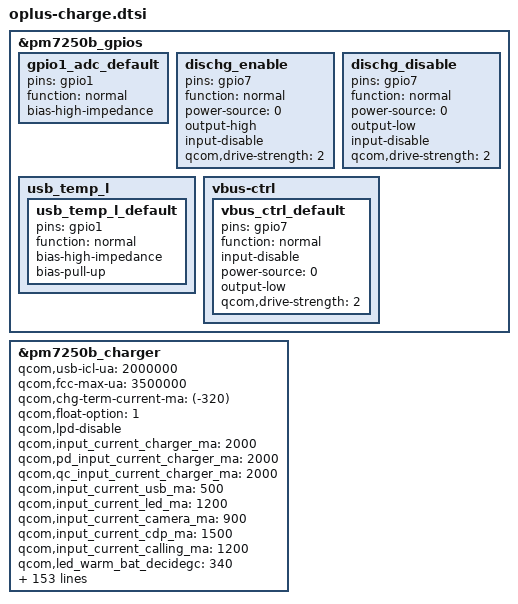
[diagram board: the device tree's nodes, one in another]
&pm7250b_gpios {
	gpio1_adc_default: gpio1_adc_default {
		pins = "gpio1"; /* GPIO 1 */
		function = "normal"; /* normal */
		bias-high-impedance; /* DISABLE GPIO1 for ADC*/
	};

	dischg_enable: dischg_enable {
		pins = "gpio7";
		function = "normal";
		power-source = <0>;
		output-high;
		input-disable;
		qcom,drive-strength = <2>;
	};

	dischg_disable: dischg_disable {
		pins = "gpio7";
		function = "normal";
		power-source = <0>;
		output-low;
		input-disable;
		qcom,drive-strength = <2>;
	};

	usb_temp_l {
		usb_temp_l_default: usb_temp_l_default {
			pins = "gpio1";
			function = "normal"; /* normal */
			bias-high-impedance;
			bias-pull-up;
		};
	};

	vbus-ctrl {
		vbus_ctrl_default: vbus_ctrl_default {
			pins = "gpio7";
			function = "normal";
			input-disable;
			power-source = <0>;
			output-low;
			qcom,drive-strength = <2>;
		};
	};
};


&pm7250b_charger {
	/* qcom options */
	qcom,usb-icl-ua = <2000000>;
	qcom,fcc-max-ua = <3500000>;
	qcom,chg-term-current-ma = <(-320)>;
	/*qcom,hvdcp-disable;*/
	qcom,float-option = <1>;
	qcom,lpd-disable;

	//for oplus chg framework:
	qcom,input_current_charger_ma = <2000>;
	qcom,pd_input_current_charger_ma = <2000>;
	qcom,qc_input_current_charger_ma = <2000>;
	qcom,input_current_usb_ma = <500>;
	qcom,input_current_led_ma = <1200>;
	qcom,input_current_camera_ma = <900>;
	qcom,input_current_cdp_ma = <1500>;
	qcom,input_current_calling_ma = <1200>;

	qcom,led_warm_bat_decidegc = <340>;	/* 34C ~ 37C */
	qcom,led_high_bat_decidegc = <370>;	/* > 37C */
	qcom,input_current_led_ma_normal = <2000>;	/* <= 34C */
	qcom,input_current_led_ma_warm = <1500>;	/* 34C ~ 37C */
	qcom,input_current_led_ma_high = <1000>;	/* > 37C */

	qcom,iterm_ma = <260>; 			/* 0.05C + 10mA */
	qcom,recharge-mv = <100>;
	qcom,batt_capacity_mah = <4890>;	/* rated capacity */

	qcom,removed_bat_decidegc = <400>;	/* < -40C */

	qcom,cold_bat_decidegc = <20>;		/* -2C ~ 0C */
	qcom,temp_cold_vfloat_mv = <3980>;
	qcom,temp_cold_fastchg_current_ma = <0>;

	qcom,little_cold_bat_decidegc = <0>;	/* 0C ~ 5C */
	qcom,temp_little_cold_vfloat_mv = <4425>;
	qcom,temp_little_cold_fastchg_current_ma = <2350>;
	qcom,temp_little_cold_fastchg_current_ma_high = <2350>;
	qcom,temp_little_cold_fastchg_current_ma_low = <1400>;
	qcom,qc_temp_little_cold_fastchg_current_ma_high = <2350>;
	qcom,qc_temp_little_cold_fastchg_current_ma_low = <1400>;
	qcom,pd_temp_little_cold_fastchg_current_ma_high = <2350>;
	qcom,pd_temp_little_cold_fastchg_current_ma_low = <2350>;

	qcom,cool_bat_decidegc = <50>;		/* 5C~12C */
	qcom,temp_cool_vfloat_mv = <4425>;
	qcom,temp_cool_fastchg_current_ma_high = <2350>;
	qcom,temp_cool_fastchg_current_ma_low = <2350>;
	qcom,qc_temp_cool_fastchg_current_ma_high = <2350>;
	qcom,qc_temp_cool_fastchg_current_ma_low = <2350>;
	qcom,pd_temp_cool_fastchg_current_ma_high = <2350>;
	qcom,pd_temp_cool_fastchg_current_ma_low = <2350>;

	qcom,little_cool_bat_decidegc = <120>;	/* 12C ~ 16C */
	qcom,temp_little_cool_vfloat_mv = <4425>;
	qcom,temp_little_cool_fastchg_current_ma = <3350>;
	qcom,temp_little_cool_fastchg_current_ma_high = <3350>;
	qcom,temp_little_cool_fastchg_current_ma_low = <2350>;
	qcom,qc_temp_little_cool_fastchg_current_ma_high = <3350>;
	qcom,qc_temp_little_cool_fastchg_current_ma_low = <2350>;
	qcom,pd_temp_little_cool_fastchg_current_ma = <2100>;

	qcom,normal_bat_decidegc = <160>;	/* 16C ~ 45C */
	qcom,temp_normal_vfloat_mv = <4425>;
	qcom,temp_normal_fastchg_current_ma = <3350>;
	qcom,pd_temp_normal_fastchg_current_ma = <3350>;
	qcom,qc_temp_normal_fastchg_current_ma = <3350>;

	qcom,normal_phase1_bat_decidegc = <160>;       /* 16C ~ 22C */
	qcom,temp_normal_phase1_vfloat_mv = <4425>;
	qcom,temp_normal_phase1_fastchg_current_ma = <3180>;

	qcom,normal_phase2_bat_decidegc = <220>;       /* 22C ~ 34C */
	qcom,temp_normal_phase2_vfloat_mv = <4425>;
	qcom,temp_normal_phase2_fastchg_current_ma_high = <3350>;
	qcom,temp_normal_phase2_fastchg_current_ma_low = <3180>;

	qcom,normal_phase3_bat_decidegc = <320>;       /* 34 ~ 37C */
	qcom,temp_normal_phase3_vfloat_mv = <4425>;
	qcom,temp_normal_phase3_fastchg_current_ma_high = <2800>;
	qcom,temp_normal_phase3_fastchg_current_ma_low = <2800>;

	qcom,normal_phase4_bat_decidegc = <370>;       /* 37C ~ 40C */
	qcom,temp_normal_phase4_vfloat_mv = <4425>;
	qcom,temp_normal_phase4_fastchg_current_ma_high = <2200>;
	qcom,temp_normal_phase4_fastchg_current_ma_low = <2200>;

	qcom,normal_phase5_bat_decidegc = <400>;       /* 40C ~ 42C */
	qcom,temp_normal_phase5_vfloat_mv = <4425>;
	qcom,temp_normal_phase5_fastchg_current_ma = <2000>;

	qcom,normal_phase6_bat_decidegc = <420>;       /* 42C ~ 45C */
	qcom,temp_normal_phase6_vfloat_mv = <4425>;
	qcom,temp_normal_phase6_fastchg_current_ma = <1450>;

	qcom,warm_bat_decidegc = <450>;		/* 45C ~ 50C */
	qcom,temp_warm_vfloat_mv = <4120>;
	qcom,temp_warm_fastchg_current_ma = <1400>;
	qcom,temp_warm_fastchg_current_ma_led_on = <500>;
	qcom,qc_temp_warm_fastchg_current_ma = <1400>;
	qcom,pd_temp_warm_fastchg_current_ma = <1400>;

	//qcom,hot_bat_decidegc = <530>;
	qcom,hot_bat_decidegc = <500>;

	qcom,non_standard_vfloat_mv = <4425>;
	qcom,non_standard_fastchg_current_ma = <512>;
	qcom,short_c_bat_cv_mv = <4330>;
	qcom,short_c_bat_vfloat_mv = <3800>;
	qcom,short_c_bat_fastchg_current_ma = <512>;

	qcom,cold_vfloat_sw_limit = <3930>;
	qcom,little_cold_vfloat_sw_limit = <4385>;
	qcom,cool_vfloat_sw_limit = <4385>;
	qcom,little_cool_vfloat_sw_limit = <4385>;
	qcom,normal_vfloat_sw_limit = <4385>;
	qcom,warm_vfloat_sw_limit = <4080>;
	qcom,non_standard_vfloat_sw_limit = <4385>;
	qcom,short_c_bat_vfloat_sw_limit = <3750>;

	qcom,max_chg_time_sec = <72000>;
	qcom,charger_hv_thr = <10000>;
	qcom,charger_recv_thr = <9700>;
	qcom,charger_lv_thr = <3400>;
	qcom,vbatt_full_thr = <4400>;
	qcom,vbatt_hv_thr = <4550>;
	qcom,vfloat_step_mv = <10>;

	qcom,non_standard_vfloat_over_sw_limit = <4440>;
	qcom,cold_vfloat_over_sw_limit = <3985>;
	qcom,little_cold_vfloat_over_sw_limit = <4440>;
	qcom,cool_vfloat_over_sw_limit = <4440>;
	qcom,little_cool_vfloat_over_sw_limit = <4440>;
	qcom,normal_vfloat_over_sw_limit = <4440>;
	qcom,warm_vfloat_over_sw_limit = <4135>;

	qcom,vbatt_power_off = <3300>;
	qcom,vbatt_soc_1 = <3410>;
	qcom,vbatt_num = <1>;

	qcom,normal_vterm_hw_inc = <18>;
	qcom,non_normal_vterm_hw_inc = <18>;

	qcom,default_iterm_ma = <260>;
	qcom,default_temp_normal_fastchg_current_ma = <3350>;
	qcom,default_normal_vfloat_sw_limit = <4385>;
	qcom,default_temp_normal_vfloat_mv = <4425>;
	qcom,default_normal_vfloat_over_sw_limit = <4440>;

	qcom,normal_current_cdp_ma = <1500>;

	qcom,offset_temp = <0>;
	qcom,check_batt_full_by_sw;

	qcom,chg_ctrl_by_lcd;
	qcom,chg_ctrl_by_calling;
	qcom,chg_ctrl_by_camera;
	qcom,sw_vfloat_over_protect_enable;

	//for PD9V or QC9V
	qcom,vbatt_pdqc_to_5v_thr = <3400>;
	qcom,dual_charger_support = <1>;

	/* skin thermal temp adjust the normal charger path current */
	op,nor_skin_thermal_high_threshold = <45000>;
	op,nor_skin_thermal_pre_high_threshold = <43000>;
	op,nor_skin_thermal_warm_threshold = <41000>;
	op,nor_skin_thermal_pre_warm_threshold = <39000>;
	op,nor_skin_thermal_normal_threshold = <37000>;
	op,input_current_led_ma_skin_normal = <2000>;	/* < 39C */
	op,input_current_led_ma_skin_warm = <1500>;	/*  41C */
	op,input_current_led_ma_skin_med = <1200>;	/* 43C  */
	op,input_current_led_ma_skin_high = <900>;	/* > 45C */

	chg-gpio-uart-tx = <&tlmm 25 0x00>;
	chg-gpio-uart-rx = <&tlmm 26 0x00>;

	/* gpio options */
	qcom,dischg-gpio = <&pm7250b_gpios 7 0x00>;
	//pinctrl-names = "dischg_enable", "dischg_disable", "default", "default";
	pinctrl-names = "dischg_enable", "dischg_disable", "gpio1_adc_default";
	pinctrl-0 = <&dischg_enable>;
	pinctrl-1 = <&dischg_disable>;
	pinctrl-2 = <&gpio1_adc_default>;
	//pinctrl-3 = <&gpio4_adc_default>;
};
